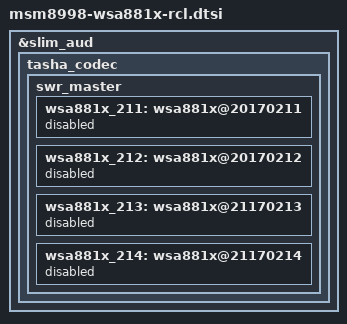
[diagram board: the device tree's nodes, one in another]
/* Copyright (c) 2016, The Linux Foundation. All rights reserved.
 *
 * This program is free software; you can redistribute it and/or modify
 * it under the terms of the GNU General Public License version 2 and
 * only version 2 as published by the Free Software Foundation.
 *
 * This program is distributed in the hope that it will be useful,
 * but WITHOUT ANY WARRANTY; without even the implied warranty of
 * MERCHANTABILITY or FITNESS FOR A PARTICULAR PURPOSE.  See the
 * GNU General Public License for more details.
 */

#include "msm8998-wcd-rcl.dtsi"

&slim_aud {
	tasha_codec {
		swr_master {
			wsa881x_211: wsa881x@20170211 {
				status = "disabled";
			};

			wsa881x_212: wsa881x@20170212 {
				status = "disabled";
			};

			wsa881x_213: wsa881x@21170213 {
				status = "disabled";
			};

			wsa881x_214: wsa881x@21170214 {
				status = "disabled";
			};
		};
	};
};
